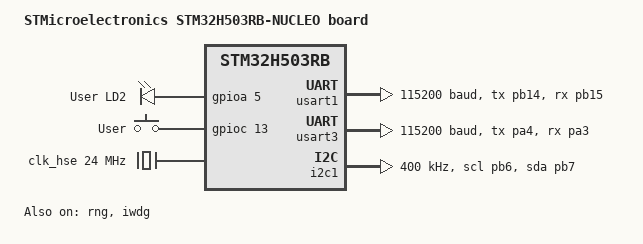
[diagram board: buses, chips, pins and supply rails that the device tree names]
/*
 * Copyright (c) 2024 Arrow Electronics.
 *
 * SPDX-License-Identifier: Apache-2.0
 */

/dts-v1/;
#include <st/h5/stm32h503Xb.dtsi>
#include <st/h5/stm32h503rbtx-pinctrl.dtsi>
#include "arduino_r3_connector.dtsi"
#include "st_morpho_connector.dtsi"
#include <zephyr/dt-bindings/input/input-event-codes.h>


/ {
	model = "STMicroelectronics STM32H503RB-NUCLEO board";
	compatible = "st,stm32h503rb-nucleo";

	#address-cells = <1>;
	#size-cells = <1>;

	chosen {
		zephyr,console = &usart3;
		zephyr,shell-uart = &usart3;
		zephyr,sram = &sram0;
		zephyr,flash = &flash0;
	};

	leds: leds {
		compatible = "gpio-leds";
		green_led_2: led_2 {
			gpios = <&gpioa 5 GPIO_ACTIVE_HIGH>;
			label = "User LD2";
		};
	};

	gpio_keys {
		compatible = "gpio-keys";
		user_button: button {
			label = "User";
			gpios = <&gpioc 13 GPIO_ACTIVE_HIGH>;
			zephyr,code = <INPUT_KEY_0>;
		};
	};

	aliases {
		led0 = &green_led_2;
		sw0 = &user_button;
		watchdog0 = &iwdg;
	};
};

&clk_csi {
	status = "okay";
};

&clk_hsi {
	status = "okay";
};

&clk_hsi48 {
	status = "okay";
};

&clk_hse {
	clock-frequency = <DT_FREQ_M(24)>;
	status = "okay";
};

&pll {
	div-m = <2>;
	mul-n = <40>;
	div-p = <2>;
	div-q = <2>;
	div-r = <2>;
	clocks = <&clk_hse>;
	status = "okay";
};

&rcc {
	clocks = <&pll>;
	clock-frequency = <DT_FREQ_M(240)>;
	ahb-prescaler = <1>;
	apb1-prescaler = <1>;
	apb2-prescaler = <1>;
	apb3-prescaler = <1>;
};

&usart1 {
	pinctrl-0 = <&usart1_tx_pb14 &usart1_rx_pb15>;
	pinctrl-names = "default";
	current-speed = <115200>;
	status = "okay";
};

&usart3 {
	pinctrl-0 = <&usart3_tx_pa4 &usart3_rx_pa3>;
	pinctrl-names = "default";
	current-speed = <115200>;
	status = "okay";
};

&rng {
	status = "okay";
};

&iwdg {
	status = "okay";
};

&i2c1 {
	pinctrl-0 = <&i2c1_scl_pb6 &i2c1_sda_pb7>;
	pinctrl-names = "default";
	clock-frequency = <I2C_BITRATE_FAST>;
	status = "okay";
};
